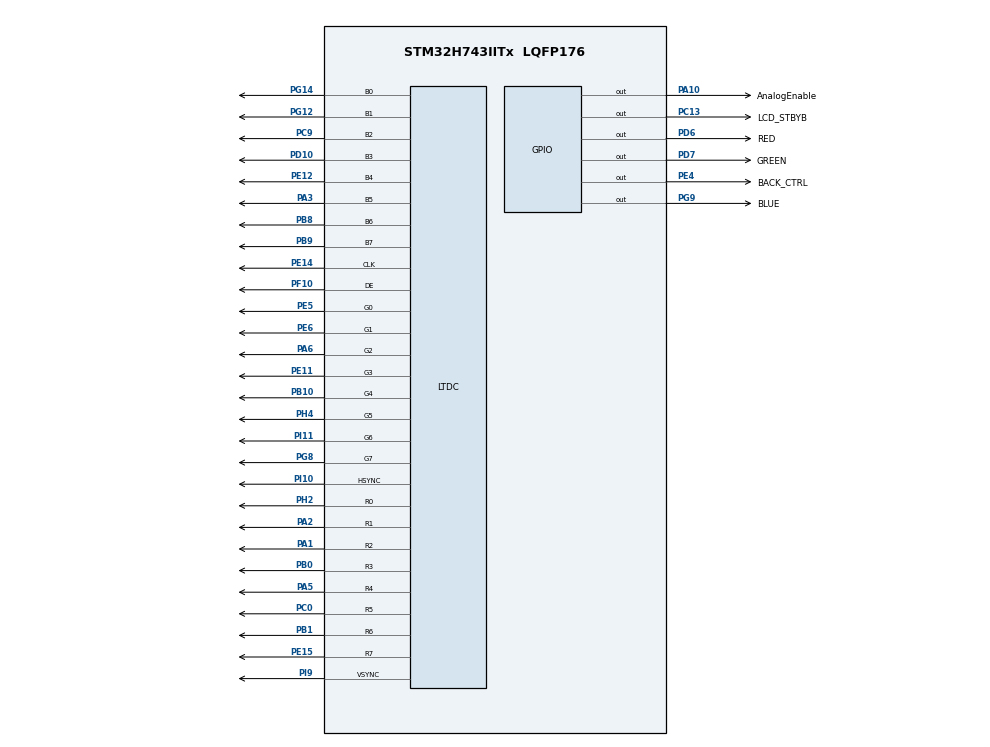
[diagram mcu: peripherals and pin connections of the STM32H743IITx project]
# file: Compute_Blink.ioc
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LTDC.ActiveW=800
LTDC.Blue=255
LTDC.HBP=88
LTDC.HFP=40
LTDC.Red=255
LTDC.VBP=32
LTDC.VFP=13
Mcu.Family=STM32H7
Mcu.Name=STM32H743IITx
Mcu.Package=LQFP176
NVIC.PriorityGroup=NVIC_PRIORITYGROUP_4
PA1.Mode=RGB888
PA1.Signal=LTDC_R2
PA10.GPIO_Label=AnalogEnable
PA10.Signal=GPIO_Output
PA2.Mode=RGB888
PA2.Signal=LTDC_R1
PA3.Mode=RGB888
PA3.Signal=LTDC_B5
PA5.Mode=RGB888
PA5.Signal=LTDC_R4
PA6.Mode=RGB888
PA6.Signal=LTDC_G2
PB0.Mode=RGB888
PB0.Signal=LTDC_R3
PB1.Mode=RGB888
PB1.Signal=LTDC_R6
PB10.Mode=RGB888
PB10.Signal=LTDC_G4
PB8.Mode=RGB888
PB8.Signal=LTDC_B6
PB9.Mode=RGB888
PB9.Signal=LTDC_B7
PC0.Mode=RGB888
PC0.Signal=LTDC_R5
PC13.GPIO_Label=LCD_STBYB
PC13.Signal=GPIO_Output
PC14-OSC32_IN.Mode=LSE-External-Oscillator
PC14-OSC32_IN.Signal=RCC_OSC32_IN
PC15-OSC32_OUT.Mode=LSE-External-Oscillator
PC15-OSC32_OUT.Signal=RCC_OSC32_OUT
PC9.Mode=RGB888
PC9.Signal=LTDC_B2
PD10.Mode=RGB888
PD10.Signal=LTDC_B3
PD6.GPIO_Label=RED
PD6.Signal=GPIO_Output
PD7.GPIO_Label=GREEN
PD7.Signal=GPIO_Output
PE11.Mode=RGB888
PE11.Signal=LTDC_G3
PE12.Mode=RGB888
PE12.Signal=LTDC_B4
PE14.Mode=RGB888
PE14.Signal=LTDC_CLK
PE15.Mode=RGB888
PE15.Signal=LTDC_R7
PE4.GPIO_Label=BACK_CTRL
PE4.Signal=GPIO_Output
PE5.Mode=RGB888
PE5.Signal=LTDC_G0
PE6.Mode=RGB888
PE6.Signal=LTDC_G1
PF10.Mode=RGB888
PF10.Signal=LTDC_DE
PG12.Mode=RGB888
PG12.Signal=LTDC_B1
PG14.Mode=RGB888
PG14.Signal=LTDC_B0
PG8.Mode=RGB888
PG8.Signal=LTDC_G7
PG9.GPIO_Label=BLUE
PG9.Signal=GPIO_Output
PH0-OSC_IN.Mode=HSE-External-Oscillator
PH0-OSC_IN.Signal=RCC_OSC_IN
PH1-OSC_OUT.Mode=HSE-External-Oscillator
PH1-OSC_OUT.Signal=RCC_OSC_OUT
PH2.Mode=RGB888
PH2.Signal=LTDC_R0
PH4.Mode=RGB888
PH4.Signal=LTDC_G5
PI10.Mode=RGB888
PI10.Signal=LTDC_HSYNC
PI11.Mode=RGB888
PI11.Signal=LTDC_G6
PI9.Mode=RGB888
PI9.Signal=LTDC_VSYNC
ProjectManager.HeapSize=0x200
ProjectManager.StackSize=0x400
ProjectManager.TargetToolchain=SW4STM32
RCC.ADCFreq_Value=32250000
RCC.APB1Freq_Value=100000000
RCC.APB2Freq_Value=100000000
RCC.APB3Freq_Value=100000000
RCC.APB4Freq_Value=100000000
RCC.CortexFreq_Value=400000000
RCC.D1PPRE=RCC_APB3_DIV2
RCC.D2PPRE1=RCC_APB1_DIV2
RCC.D2PPRE2=RCC_APB2_DIV2
RCC.D3PPRE=RCC_APB4_DIV2
RCC.DIVM1=1
RCC.DIVN1=50
RCC.HCLKFreq_Value=200000000
RCC.HPRE=RCC_HCLK_DIV2
RCC.HSE_VALUE=16000000
RCC.PLLSourceVirtual=RCC_PLLSOURCE_HSE
RCC.SYSCLKFreq_VALUE=400000000
RCC.SYSCLKSource=RCC_SYSCLKSOURCE_PLLCLK
RCC.USBFreq_Value=400000000
board=Compute_Blink

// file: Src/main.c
/**
  ******************************************************************************
  * @file           : main.c
  * @brief          : Main program body
  ******************************************************************************
  ** This notice applies to any and all portions of this file
  * that are not between comment pairs USER CODE BEGIN and
  * USER CODE END. Other portions of this file, whether
  * inserted by the user or by software development tools
  * are owned by their respective copyright owners.
  *
  * COPYRIGHT(c) 2018 STMicroelectronics
  *
  * Redistribution and use in source and binary forms, with or without modification,
  * are permitted provided that the following conditions are met:
  *   1. Redistributions of source code must retain the above copyright notice,
  *      this list of conditions and the following disclaimer.
  *   2. Redistributions in binary form must reproduce the above copyright notice,
  *      this list of conditions and the following disclaimer in the documentation
  *      and/or other materials provided with the distribution.
  *   3. Neither the name of STMicroelectronics nor the names of its contributors
  *      may be used to endorse or promote products derived from this software
  *      without specific prior written permission.
  *
  * THIS SOFTWARE IS PROVIDED BY THE COPYRIGHT HOLDERS AND CONTRIBUTORS "AS IS"
  * AND ANY EXPRESS OR IMPLIED WARRANTIES, INCLUDING, BUT NOT LIMITED TO, THE
  * IMPLIED WARRANTIES OF MERCHANTABILITY AND FITNESS FOR A PARTICULAR PURPOSE ARE
  * DISCLAIMED. IN NO EVENT SHALL THE COPYRIGHT HOLDER OR CONTRIBUTORS BE LIABLE
  * FOR ANY DIRECT, INDIRECT, INCIDENTAL, SPECIAL, EXEMPLARY, OR CONSEQUENTIAL
  * DAMAGES (INCLUDING, BUT NOT LIMITED TO, PROCUREMENT OF SUBSTITUTE GOODS OR
  * SERVICES; LOSS OF USE, DATA, OR PROFITS; OR BUSINESS INTERRUPTION) HOWEVER
  * CAUSED AND ON ANY THEORY OF LIABILITY, WHETHER IN CONTRACT, STRICT LIABILITY,
  * OR TORT (INCLUDING NEGLIGENCE OR OTHERWISE) ARISING IN ANY WAY OUT OF THE USE
  * OF THIS SOFTWARE, EVEN IF ADVISED OF THE POSSIBILITY OF SUCH DAMAGE.
  *
  ******************************************************************************
  */
#include "main.h"
#include "stm32h7xx_hal.h"

LTDC_HandleTypeDef hltdc;

/* USER CODE BEGIN PV */
/* Private variables ---------------------------------------------------------*/

/* USER CODE END PV */

void SystemClock_Config(void);
static void MX_GPIO_Init(void);
static void MX_LTDC_Init(void);

/* USER CODE BEGIN PFP */
/* Private function prototypes -----------------------------------------------*/

/* USER CODE END PFP */

int main(void)
{

  /* MCU Configuration----------------------------------------------------------*/

  /* Reset of all peripherals, Initializes the Flash interface and the Systick. */
  HAL_Init();

  /* Configure the system clock */
  SystemClock_Config();

  /* Initialize all configured peripherals */
  MX_GPIO_Init();
  MX_LTDC_Init();
  /* USER CODE BEGIN 2 */

  HAL_GPIO_WritePin(AnalogEnable_GPIO_Port, AnalogEnable_Pin, 1);
  HAL_GPIO_WritePin(BACK_CTRL_GPIO_Port, BACK_CTRL_Pin, 0);
  BLUE_GPIO_Port->BSRRL = BLUE_Pin;

  /* USER CODE END 2 */

  /* Infinite loop */
  while (1)
  {

  /* USER CODE BEGIN 3 */
	  //HAL_GPIO_WritePin(RED_GPIO_Port, RED_Pin, 0);
	  //HAL_GPIO_WritePin(GREEN_GPIO_Port, GREEN_Pin, 0);
	  //HAL_GPIO_WritePin(BLUE_GPIO_Port, BLUE_Pin, 0);
	  //HAL_GPIO_WritePin(RED_GPIO_Port, RED_Pin, 1);
	  //HAL_GPIO_WritePin(GREEN_GPIO_Port, GREEN_Pin, 1);
	  //HAL_GPIO_WritePin(BLUE_GPIO_Port, BLUE_Pin, 1);

  }
  /* USER CODE END 3 */

}

void SystemClock_Config(void)
{

  RCC_OscInitTypeDef RCC_OscInitStruct;
  RCC_ClkInitTypeDef RCC_ClkInitStruct;
  RCC_PeriphCLKInitTypeDef PeriphClkInitStruct;

    /**Supply configuration update enable
    */
  MODIFY_REG(PWR->CR3, PWR_CR3_SCUEN, 0);

    /**Configure the main internal regulator output voltage
    */
  __HAL_PWR_VOLTAGESCALING_CONFIG(PWR_REGULATOR_VOLTAGE_SCALE1);

  while ((PWR->D3CR & (PWR_D3CR_VOSRDY)) != PWR_D3CR_VOSRDY)
  {

  }
    /**Macro to configure the PLL clock source
    */
  __HAL_RCC_PLL_PLLSOURCE_CONFIG(RCC_PLLSOURCE_HSE);

    /**Initializes the CPU, AHB and APB busses clocks
    */
  RCC_OscInitStruct.OscillatorType = RCC_OSCILLATORTYPE_HSE;
  RCC_OscInitStruct.HSEState = RCC_HSE_ON;
  RCC_OscInitStruct.PLL.PLLState = RCC_PLL_ON;
  RCC_OscInitStruct.PLL.PLLSource = RCC_PLLSOURCE_HSE;
  RCC_OscInitStruct.PLL.PLLM = 1;
  RCC_OscInitStruct.PLL.PLLN = 50;
  RCC_OscInitStruct.PLL.PLLP = 2;
  RCC_OscInitStruct.PLL.PLLQ = 2;
  RCC_OscInitStruct.PLL.PLLR = 2;
  RCC_OscInitStruct.PLL.PLLRGE = RCC_PLL1VCIRANGE_3;
  RCC_OscInitStruct.PLL.PLLVCOSEL = RCC_PLL1VCOWIDE;
  RCC_OscInitStruct.PLL.PLLFRACN = 0;
  if (HAL_RCC_OscConfig(&RCC_OscInitStruct) != HAL_OK)
  {
    _Error_Handler(__FILE__, __LINE__);
  }

    /**Initializes the CPU, AHB and APB busses clocks
    */
  RCC_ClkInitStruct.ClockType = RCC_CLOCKTYPE_HCLK|RCC_CLOCKTYPE_SYSCLK
                              |RCC_CLOCKTYPE_PCLK1|RCC_CLOCKTYPE_PCLK2
                              |RCC_CLOCKTYPE_D3PCLK1|RCC_CLOCKTYPE_D1PCLK1;
  RCC_ClkInitStruct.SYSCLKSource = RCC_SYSCLKSOURCE_PLLCLK;
  RCC_ClkInitStruct.SYSCLKDivider = RCC_SYSCLK_DIV1;
  RCC_ClkInitStruct.AHBCLKDivider = RCC_HCLK_DIV2;
  RCC_ClkInitStruct.APB3CLKDivider = RCC_APB3_DIV2;
  RCC_ClkInitStruct.APB1CLKDivider = RCC_APB1_DIV2;
  RCC_ClkInitStruct.APB2CLKDivider = RCC_APB2_DIV2;
  RCC_ClkInitStruct.APB4CLKDivider = RCC_APB4_DIV2;

  if (HAL_RCC_ClockConfig(&RCC_ClkInitStruct, FLASH_LATENCY_2) != HAL_OK)
  {
    _Error_Handler(__FILE__, __LINE__);
  }

  PeriphClkInitStruct.PeriphClockSelection = RCC_PERIPHCLK_LTDC;
  PeriphClkInitStruct.PLL3.PLL3M = 32;
  PeriphClkInitStruct.PLL3.PLL3N = 129;
  PeriphClkInitStruct.PLL3.PLL3P = 2;
  PeriphClkInitStruct.PLL3.PLL3Q = 2;
  PeriphClkInitStruct.PLL3.PLL3R = 2;
  PeriphClkInitStruct.PLL3.PLL3RGE = RCC_PLL3VCIRANGE_3;
  PeriphClkInitStruct.PLL3.PLL3VCOSEL = RCC_PLL3VCOWIDE;
  PeriphClkInitStruct.PLL3.PLL3FRACN = 0;
  if (HAL_RCCEx_PeriphCLKConfig(&PeriphClkInitStruct) != HAL_OK)
  {
    _Error_Handler(__FILE__, __LINE__);
  }

    /**Configure the Systick interrupt time
    */
  HAL_SYSTICK_Config(SystemCoreClock/1000);

    /**Configure the Systick
    */
  HAL_SYSTICK_CLKSourceConfig(SYSTICK_CLKSOURCE_HCLK);

  /* SysTick_IRQn interrupt configuration */
  HAL_NVIC_SetPriority(SysTick_IRQn, 0, 0);
}

/* LTDC init function */
static void MX_LTDC_Init(void)
{

  LTDC_LayerCfgTypeDef pLayerCfg;
  LTDC_LayerCfgTypeDef pLayerCfg1;

  hltdc.Instance = LTDC;
  hltdc.Init.HSPolarity = LTDC_HSPOLARITY_AL;
  hltdc.Init.VSPolarity = LTDC_VSPOLARITY_AL;
  hltdc.Init.DEPolarity = LTDC_DEPOLARITY_AL;
  hltdc.Init.PCPolarity = LTDC_PCPOLARITY_IPC;
  hltdc.Init.HorizontalSync = 7;
  hltdc.Init.VerticalSync = 3;
  hltdc.Init.AccumulatedHBP = 95;
  hltdc.Init.AccumulatedVBP = 35;
  hltdc.Init.AccumulatedActiveW = 895;
  hltdc.Init.AccumulatedActiveH = 515;
  hltdc.Init.TotalWidth = 935;
  hltdc.Init.TotalHeigh = 528;
  hltdc.Init.Backcolor.Blue = 255;
  hltdc.Init.Backcolor.Green = 0;
  hltdc.Init.Backcolor.Red = 255;
  if (HAL_LTDC_Init(&hltdc) != HAL_OK)
  {
    _Error_Handler(__FILE__, __LINE__);
  }

  pLayerCfg.WindowX0 = 0;
  pLayerCfg.WindowX1 = 0;
  pLayerCfg.WindowY0 = 0;
  pLayerCfg.WindowY1 = 0;
  pLayerCfg.PixelFormat = LTDC_PIXEL_FORMAT_ARGB8888;
  pLayerCfg.Alpha = 0;
  pLayerCfg.Alpha0 = 0;
  pLayerCfg.BlendingFactor1 = LTDC_BLENDING_FACTOR1_CA;
  pLayerCfg.BlendingFactor2 = LTDC_BLENDING_FACTOR2_CA;
  pLayerCfg.FBStartAdress = 0;
  pLayerCfg.ImageWidth = 0;
  pLayerCfg.ImageHeight = 0;
  pLayerCfg.Backcolor.Blue = 0;
  pLayerCfg.Backcolor.Green = 0;
  pLayerCfg.Backcolor.Red = 0;
  if (HAL_LTDC_ConfigLayer(&hltdc, &pLayerCfg, 0) != HAL_OK)
  {
    _Error_Handler(__FILE__, __LINE__);
  }

  pLayerCfg1.WindowX0 = 0;
  pLayerCfg1.WindowX1 = 0;
  pLayerCfg1.WindowY0 = 0;
  pLayerCfg1.WindowY1 = 0;
  pLayerCfg1.PixelFormat = LTDC_PIXEL_FORMAT_ARGB8888;
  pLayerCfg1.Alpha = 0;
  pLayerCfg1.Alpha0 = 0;
  pLayerCfg1.BlendingFactor1 = LTDC_BLENDING_FACTOR1_CA;
  pLayerCfg1.BlendingFactor2 = LTDC_BLENDING_FACTOR2_CA;
  pLayerCfg1.FBStartAdress = 0;
  pLayerCfg1.ImageWidth = 0;
  pLayerCfg1.ImageHeight = 0;
  pLayerCfg1.Backcolor.Blue = 0;
  pLayerCfg1.Backcolor.Green = 0;
  pLayerCfg1.Backcolor.Red = 0;
  if (HAL_LTDC_ConfigLayer(&hltdc, &pLayerCfg1, 1) != HAL_OK)
  {
    _Error_Handler(__FILE__, __LINE__);
  }

}

/** Configure pins as
        * Analog
        * Input
        * Output
        * EVENT_OUT
        * EXTI
*/
static void MX_GPIO_Init(void)
{

  GPIO_InitTypeDef GPIO_InitStruct;

  /* GPIO Ports Clock Enable */
  __HAL_RCC_GPIOE_CLK_ENABLE();
  __HAL_RCC_GPIOC_CLK_ENABLE();
  __HAL_RCC_GPIOI_CLK_ENABLE();
  __HAL_RCC_GPIOF_CLK_ENABLE();
  __HAL_RCC_GPIOH_CLK_ENABLE();
  __HAL_RCC_GPIOA_CLK_ENABLE();
  __HAL_RCC_GPIOB_CLK_ENABLE();
  __HAL_RCC_GPIOD_CLK_ENABLE();
  __HAL_RCC_GPIOG_CLK_ENABLE();

  /*Configure GPIO pin Output Level */
  HAL_GPIO_WritePin(BACK_CTRL_GPIO_Port, BACK_CTRL_Pin, GPIO_PIN_RESET);

  /*Configure GPIO pin Output Level */
  HAL_GPIO_WritePin(LCD_STBYB_GPIO_Port, LCD_STBYB_Pin, GPIO_PIN_RESET);

  /*Configure GPIO pin Output Level */
  HAL_GPIO_WritePin(AnalogEnable_GPIO_Port, AnalogEnable_Pin, GPIO_PIN_RESET);

  /*Configure GPIO pin Output Level */
  HAL_GPIO_WritePin(GPIOD, RED_Pin|GREEN_Pin, GPIO_PIN_RESET);

  /*Configure GPIO pin Output Level */
  HAL_GPIO_WritePin(BLUE_GPIO_Port, BLUE_Pin, GPIO_PIN_RESET);

  /*Configure GPIO pin : BACK_CTRL_Pin */
  GPIO_InitStruct.Pin = BACK_CTRL_Pin;
  GPIO_InitStruct.Mode = GPIO_MODE_OUTPUT_PP;
  GPIO_InitStruct.Pull = GPIO_NOPULL;
  GPIO_InitStruct.Speed = GPIO_SPEED_FREQ_LOW;
  HAL_GPIO_Init(BACK_CTRL_GPIO_Port, &GPIO_InitStruct);

  /*Configure GPIO pin : LCD_STBYB_Pin */
  GPIO_InitStruct.Pin = LCD_STBYB_Pin;
  GPIO_InitStruct.Mode = GPIO_MODE_OUTPUT_PP;
  GPIO_InitStruct.Pull = GPIO_NOPULL;
  GPIO_InitStruct.Speed = GPIO_SPEED_FREQ_LOW;
  HAL_GPIO_Init(LCD_STBYB_GPIO_Port, &GPIO_InitStruct);

  /*Configure GPIO pin : AnalogEnable_Pin */
  GPIO_InitStruct.Pin = AnalogEnable_Pin;
  GPIO_InitStruct.Mode = GPIO_MODE_OUTPUT_PP;
  GPIO_InitStruct.Pull = GPIO_NOPULL;
  GPIO_InitStruct.Speed = GPIO_SPEED_FREQ_LOW;
  HAL_GPIO_Init(AnalogEnable_GPIO_Port, &GPIO_InitStruct);

  /*Configure GPIO pins : RED_Pin GREEN_Pin */
  GPIO_InitStruct.Pin = RED_Pin|GREEN_Pin;
  GPIO_InitStruct.Mode = GPIO_MODE_OUTPUT_PP;
  GPIO_InitStruct.Pull = GPIO_NOPULL;
  GPIO_InitStruct.Speed = GPIO_SPEED_FREQ_LOW;
  HAL_GPIO_Init(GPIOD, &GPIO_InitStruct);

  /*Configure GPIO pin : BLUE_Pin */
  GPIO_InitStruct.Pin = BLUE_Pin;
  GPIO_InitStruct.Mode = GPIO_MODE_OUTPUT_PP;
  GPIO_InitStruct.Pull = GPIO_NOPULL;
  GPIO_InitStruct.Speed = GPIO_SPEED_FREQ_LOW;
  HAL_GPIO_Init(BLUE_GPIO_Port, &GPIO_InitStruct);

}

void _Error_Handler(char *file, int line)
{
  while(1)
  {
  }
}

/************************ (C) COPYRIGHT STMicroelectronics *****END OF FILE****/
